VERSION ""

NS_ :

BS_:

BU_: Vector__XXX

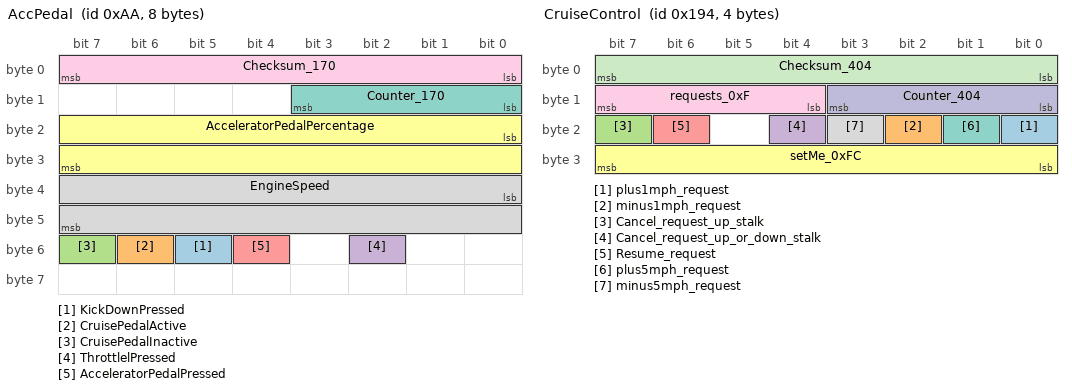
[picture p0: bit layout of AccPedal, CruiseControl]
BO_ 170 AccPedal: 8 Vector__XXX
SG_ KickDownPressed : 53|1@0+ (1,0) [0|1] "" Vector__XXX
SG_ CruisePedalActive : 54|1@0+ (1,0) [0|1] "" Vector__XXX
SG_ CruisePedalInactive : 55|1@0+ (1,0) [0|1] "" Vector__XXX
SG_ ThrottlelPressed : 50|1@0+ (1,0) [0|1] "" Vector__XXX
SG_ AcceleratorPedalPressed : 52|1@0+ (1,0) [0|1] "" Vector__XXX
SG_ AcceleratorPedalPercentage : 16|16@1+ (0.04,0) [0|100] "" Vector__XXX
SG_ Counter_170 : 8|4@1+ (1,0) [0|15] "" Vector__XXX
SG_ EngineSpeed : 32|16@1+ (0.25,0) [0|8000] "rpm" Vector__XXX
SG_ Checksum_170 : 0|8@1- (1,0) [0|127] "" Vector__XXX

BO_ 404 CruiseControl: 4 Vector__XXX
SG_ plus1mph_request : 16|1@0+ (1,0) [0|1] "" Vector__XXX
SG_ minus1mph_request : 18|1@0+ (1,0) [0|1] "" Vector__XXX
SG_ Cancel_request_up_stalk : 23|1@0+ (1,0) [0|1] "" Vector__XXX
SG_ Cancel_request_up_or_down_stalk : 20|1@0+ (1,0) [0|1] "" Vector__XXX
SG_ Resume_request : 22|1@0+ (1,0) [0|1] "" Vector__XXX
SG_ setMe_0xFC : 31|8@0+ (1,0) [0|255] "" Vector__XXX
SG_ plus5mph_request : 17|1@0+ (1,0) [0|1] "" Vector__XXX
SG_ minus5mph_request : 19|1@0+ (1,0) [0|1] "" Vector__XXX
SG_ requests_0xF : 15|4@0+ (1,0) [0|15] "" Vector__XXX
SG_ Counter_404 : 11|4@0+ (1,0) [0|15] "" Vector__XXX
SG_ Checksum_404 : 7|8@0+ (1,0) [0|15] "" Vector__XXX

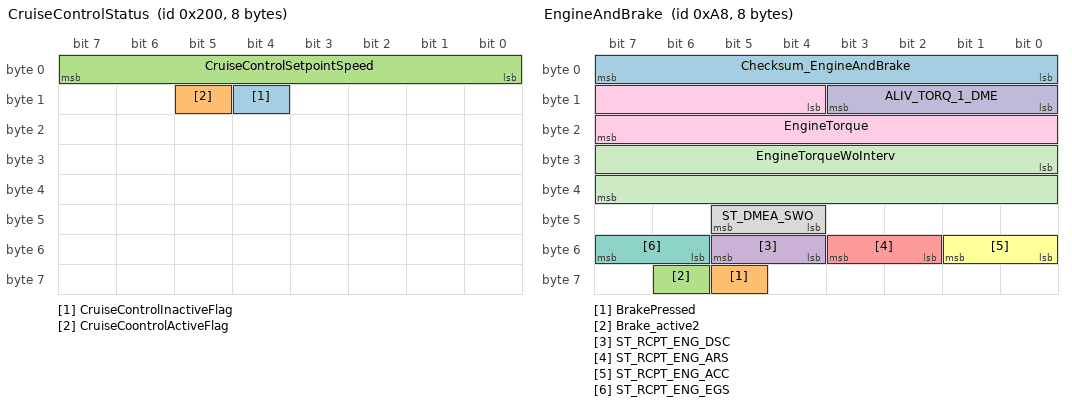
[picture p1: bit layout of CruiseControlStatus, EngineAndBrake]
BO_ 512 CruiseControlStatus: 8 Vector__XXX
SG_ CruiseControlInactiveFlag : 12|1@0+ (1,0) [0|1] "" Vector__XXX
SG_ CruiseCoontrolActiveFlag : 13|1@0+ (1,0) [0|1] "" Vector__XXX
SG_ CruiseControlSetpointSpeed : 7|8@0+ (0.25,0) [0|63.75] "mph" Vector__XXX

BO_ 168 EngineAndBrake: 8 Vector__XXX
SG_ Checksum_EngineAndBrake : 0|8@1+ (1,0) [0|255] "" Vector__XXX
SG_ BrakePressed : 61|1@0+ (1,0) [0|1] "" Vector__XXX
SG_ Brake_active2 : 62|1@0+ (1,0) [0|1] "" Vector__XXX
SG_ ST_RCPT_ENG_DSC : 52|2@1+ (1,0) [0|3] "" Vector__XXX
SG_ ST_RCPT_ENG_ARS : 50|2@1+ (1,0) [0|3] "" Vector__XXX
SG_ ST_RCPT_ENG_ACC : 48|2@1+ (1,0) [0|3] "" Vector__XXX
SG_ ST_RCPT_ENG_EGS : 54|2@1+ (1,0) [0|3] "" Vector__XXX
SG_ ST_DMEA_SWO : 44|2@1+ (1,0) [0|3] "" Vector__XXX
SG_ EngineTorque : 12|12@1- (0.03125,0) [-64|63.96875] "" Vector__XXX
SG_ ALIV_TORQ_1_DME : 8|4@1+ (1,0) [0|15] "" Vector__XXX
SG_ EngineTorqueWoInterv : 24|16@1- (0.03125,0) [-1024|1023.96875] "" Vector__XXX

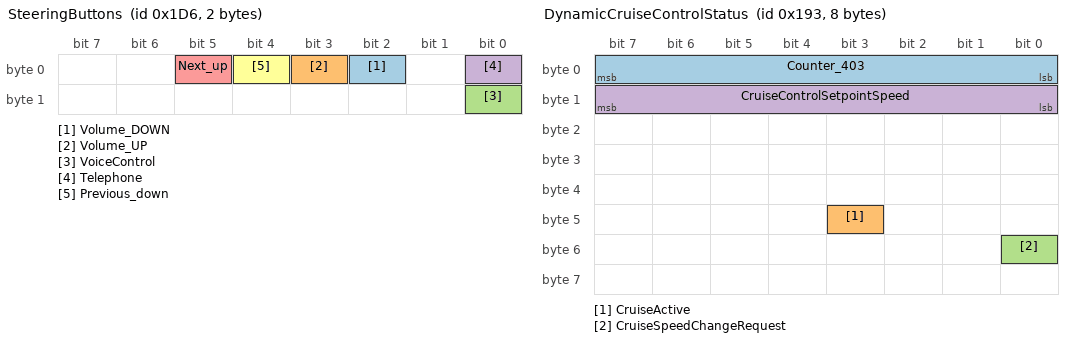
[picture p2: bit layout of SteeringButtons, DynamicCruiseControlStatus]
BO_ 470 SteeringButtons: 2 Vector__XXX
SG_ Volume_DOWN : 2|1@0+ (1,0) [0|1] "" Vector__XXX
SG_ Volume_UP : 3|1@0+ (1,0) [0|1] "" Vector__XXX
SG_ VoiceControl : 8|1@0+ (1,0) [0|1] "" Vector__XXX
SG_ Telephone : 0|1@0+ (1,0) [0|1] "" Vector__XXX
SG_ Next_up : 5|1@0+ (1,0) [0|1] "" Vector__XXX
SG_ Previous_down : 4|1@0+ (1,0) [0|1] "" Vector__XXX

BO_ 403 DynamicCruiseControlStatus: 8 Vector__XXX
SG_ Counter_403 : 7|8@0+ (1,0) [0|255] "" Vector__XXX
SG_ CruiseActive : 43|1@0+ (1,0) [0|1] "" Vector__XXX
SG_ CruiseSpeedChangeRequest : 48|1@0+ (1,0) [0|1] "" Vector__XXX
SG_ CruiseControlSetpointSpeed : 15|8@0+ (1,-2) [0|253] "kph/mph" Vector__XXX

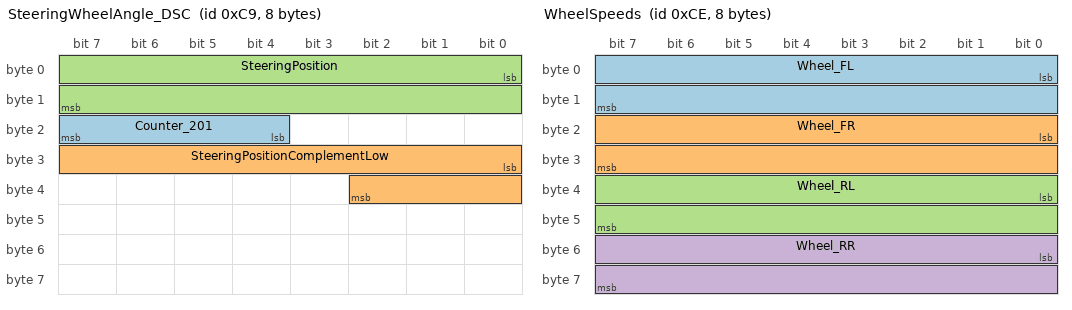
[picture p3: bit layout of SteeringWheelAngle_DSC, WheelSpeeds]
BO_ 201 SteeringWheelAngle_DSC: 8 Vector__XXX
SG_ Counter_201 : 20|4@1+ (1,0) [0|15] "" Vector__XXX
SG_ SteeringPositionComplementLow : 24|11@1- (1,0) [0|1] "" Vector__XXX
SG_ SteeringPosition : 0|16@1- (0.0428316886,0) [-600|600] "deg" Vector__XXX

BO_ 206 WheelSpeeds: 8 Vector__XXX
SG_ Wheel_FL : 0|16@1- (0.0625,0) [0|255] "kph" Vector__XXX
SG_ Wheel_FR : 16|16@1- (0.0625,0) [0|255] "kph" Vector__XXX
SG_ Wheel_RL : 32|16@1- (0.0625,0) [0|255] "kph" Vector__XXX
SG_ Wheel_RR : 48|16@1- (0.0625,0) [0|255] "kph" Vector__XXX

BO_ 884 WheelToleranceAdjustment: 8 Vector__XXX

BO_ 678 WiperSwitch: 8 Vector__XXX
SG_ AutoWipersOn : 0|1@1+ (1,0) [0|1] "" Vector__XXX

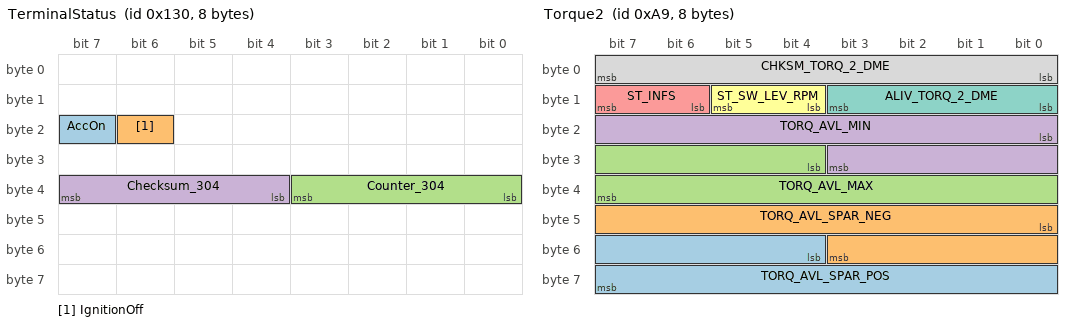
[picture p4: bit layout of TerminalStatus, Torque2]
BO_ 304 TerminalStatus: 8 Vector__XXX
SG_ AccOn : 23|1@1+ (1,0) [0|1] "" Vector__XXX
SG_ IgnitionOff : 22|1@1+ (1,0) [0|1] "" Vector__XXX
SG_ Counter_304 : 32|4@1+ (1,0) [0|15] "" Vector__XXX
SG_ Checksum_304 : 36|4@1+ (1,0) [0|15] "" Vector__XXX

BO_ 169 Torque2: 8 Vector__XXX
SG_ TORQ_AVL_SPAR_POS : 52|12@1- (0.5,0) [-1023.5|1023.5] "Nm" Vector__XXX
SG_ TORQ_AVL_SPAR_NEG : 40|12@1- (0.5,0) [-1023.5|1023.5] "Nm" Vector__XXX
SG_ TORQ_AVL_MAX : 28|12@1- (0.5,0) [-1023.5|1023.5] "Nm" Vector__XXX
SG_ TORQ_AVL_MIN : 16|12@1- (0.5,0) [-1023.5|1023.5] "Nm" Vector__XXX
SG_ ST_INFS : 14|2@1+ (1,0) [0|3] "" Vector__XXX
SG_ ST_SW_LEV_RPM : 12|2@1+ (1,0) [0|3] "" Vector__XXX
SG_ ALIV_TORQ_2_DME : 8|4@1+ (1,0) [0|15] "" Vector__XXX
SG_ CHKSM_TORQ_2_DME : 0|8@1+ (1,0) [0|255] "" Vector__XXX

BO_ 184 TorqueTransmisionRequest: 8 Vector__XXX
SG_ Checksum_184 : 0|8@1+ (1,0) [0|15] "" Vector__XXX
SG_ Counter_184 : 8|4@1+ (1,0) [0|15] "" Vector__XXX

BO_ 196 SteeringWheelAngle: 7 Vector__XXX
SG_ SteeringSpeed : 24|16@1- (0.0428316886,0) [0|255] "degree/s" Vector__XXX
SG_ SteeringPosition : 0|16@1- (0.0428316886,0) [-600|600] "degree" Vector__XXX

BO_ 180 WheelTorqueDriveTrain1: 8 Vector__XXX

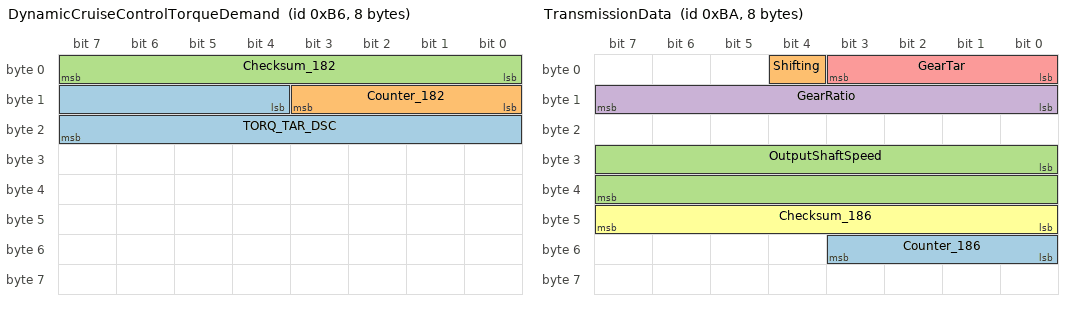
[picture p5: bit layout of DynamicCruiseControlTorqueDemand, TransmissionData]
BO_ 182 DynamicCruiseControlTorqueDemand: 8 Vector__XXX
SG_ TORQ_TAR_DSC : 12|12@1- (0.5,0) [0|1000] "" Vector__XXX
SG_ Counter_182 : 8|4@1+ (1,0) [0|14] "" Vector__XXX
SG_ Checksum_182 : 0|8@1+ (1,0) [0|15] "" Vector__XXX

BO_ 186 TransmissionData: 8 Vector__XXX
SG_ Counter_186 : 48|4@1+ (1,0) [0|14] "" Vector__XXX
SG_ Shifting : 4|1@1+ (1,0) [0|1] "" Vector__XXX
SG_ OutputShaftSpeed : 24|16@1- (0.125,0) [0|255] "rpm" Vector__XXX
SG_ GearRatio : 8|8@1+ (0.05,0) [0|12.75] "" Vector__XXX
SG_ GearTar : 0|4@1+ (1,-4) [0|11] "" Vector__XXX
SG_ Checksum_186 : 40|8@1+ (1,0) [0|15] "" Vector__XXX

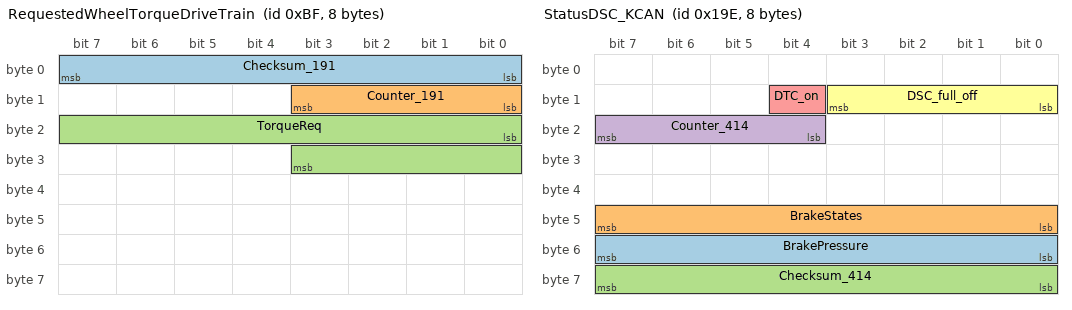
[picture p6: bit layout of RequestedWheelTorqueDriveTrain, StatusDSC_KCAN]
BO_ 191 RequestedWheelTorqueDriveTrain: 8 Vector__XXX
SG_ Checksum_191 : 0|8@1+ (1,0) [0|19] "" Vector__XXX
SG_ Counter_191 : 8|4@1- (1,0) [0|7] "" Vector__XXX
SG_ TorqueReq : 16|12@1- (0.5,350) [-674|1023.96875] "" Vector__XXX

BO_ 414 StatusDSC_KCAN: 8 Vector__XXX
SG_ BrakePressure : 48|8@1- (1,0) [0|127] "" Vector__XXX
SG_ BrakeStates : 40|8@1+ (1,0) [0|255] "" Vector__XXX
SG_ Checksum_414 : 56|8@1+ (1,0) [0|15] "" Vector__XXX
SG_ Counter_414 : 20|4@1+ (1,0) [0|15] "" Vector__XXX
SG_ DTC_on : 12|1@1+ (1,0) [0|1] "" Vector__XXX
SG_ DSC_full_off : 8|4@1+ (1,0) [0|15] "" Vector__XXX

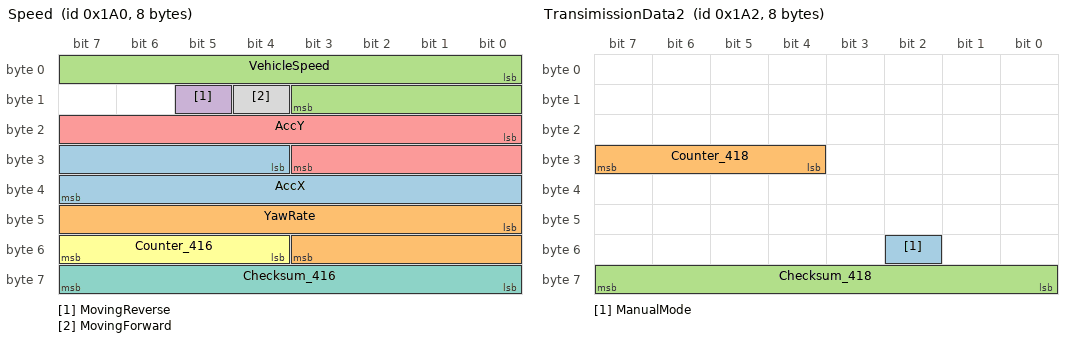
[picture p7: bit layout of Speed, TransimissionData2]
BO_ 416 Speed: 8 Vector__XXX
SG_ AccX : 28|12@1- (1,0) [0|15] "" Vector__XXX
SG_ YawRate : 40|12@1- (1,0) [0|255] "" Vector__XXX
SG_ VehicleSpeed : 0|12@1- (0.103,0) [0|210.841] "kph" Vector__XXX
SG_ MovingReverse : 13|1@1+ (1,0) [0|1] "" Vector__XXX
SG_ AccY : 16|12@1- (1,0) [0|255] "" Vector__XXX
SG_ Counter_416 : 52|4@1+ (1,0) [0|14] "" Vector__XXX
SG_ Checksum_416 : 56|8@1+ (1,0) [0|15] "" Vector__XXX
SG_ MovingForward : 12|1@1+ (1,0) [0|1] "" Vector__XXX

BO_ 418 TransimissionData2: 8 Vector__XXX
SG_ ManualMode : 50|1@0+ (1,0) [0|1] "" Vector__XXX
SG_ Counter_418 : 28|4@1+ (1,0) [0|14] "" Vector__XXX
SG_ Checksum_418 : 56|8@1+ (1,0) [0|15] "" Vector__XXX

BO_ 690 WheelPressure_KCAN: 8 Vector__XXX

BO_ 691 AccelerationData: 8 Vector__XXX

BO_ 402 GearSelectorSwitch_1: 4 Vector__XXX
SG_ Counter_402 : 24|4@1+ (1,0) [0|14] "" Vector__XXX

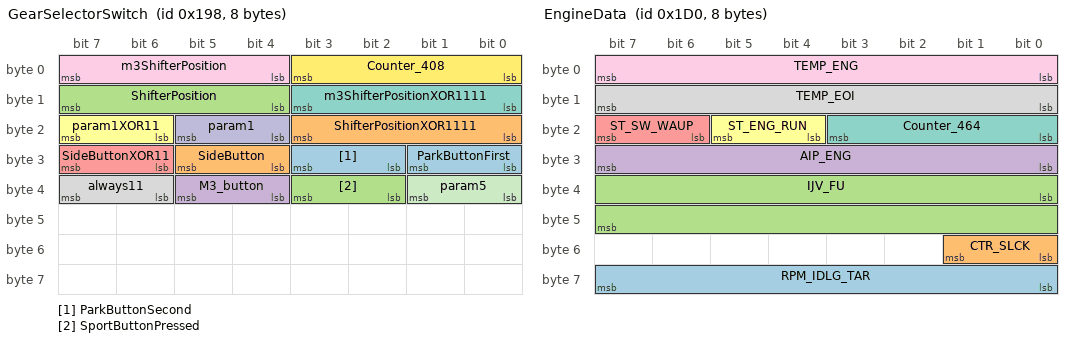
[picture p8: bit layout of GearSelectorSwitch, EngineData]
BO_ 408 GearSelectorSwitch: 8 Vector__XXX
SG_ ParkButtonSecond : 26|2@1+ (1,0) [0|3] "" Vector__XXX
SG_ SideButton : 28|2@1+ (1,0) [0|3] "" Vector__XXX
SG_ SportButtonPressed : 34|2@1+ (1,0) [0|3] "" Vector__XXX
SG_ M3_button : 36|2@1+ (1,0) [0|3] "" Vector__XXX
SG_ SideButtonXOR11 : 30|2@1+ (1,0) [0|3] "" Vector__XXX
SG_ param1XOR11 : 22|2@1+ (1,0) [0|3] "" Vector__XXX
SG_ m3ShifterPositionXOR1111 : 8|4@1+ (1,0) [0|15] "" Vector__XXX
SG_ always11 : 38|2@1+ (1,0) [0|3] "" Vector__XXX
SG_ m3ShifterPosition : 4|4@1+ (1,0) [0|15] "" Vector__XXX
SG_ param1 : 20|2@1+ (1,0) [0|3] "" Vector__XXX
SG_ param5 : 32|2@1+ (1,0) [0|3] "" Vector__XXX
SG_ Counter_408 : 0|4@1+ (1,0) [0|14] "" Vector__XXX
SG_ ParkButtonFirst : 24|2@1+ (1,0) [0|3] "" Vector__XXX
SG_ ShifterPositionXOR1111 : 16|4@1+ (1,0) [0|15] "" Vector__XXX
SG_ ShifterPosition : 12|4@1+ (1,0) [0|15] "" Vector__XXX

BO_ 422 DistanceRoute: 8 Vector__XXX

BO_ 436 InstrumentClusterStatus_KOMBI: 8 Vector__XXX
SG_ HandbrakeActive : 41|1@1+ (1,0) [0|1] "" Vector__XXX

BO_ 464 EngineData: 8 Vector__XXX
SG_ RPM_IDLG_TAR : 56|8@1+ (5,0) [0|1270] "1/min" Vector__XXX
SG_ CTR_SLCK : 48|2@1+ (1,0) [0|3] "" Vector__XXX
SG_ IJV_FU : 32|16@1+ (1,-48) [-48|65487] "C" Vector__XXX
SG_ AIP_ENG : 24|8@1+ (2,598) [600|1106] "hPa" Vector__XXX
SG_ ST_SW_WAUP : 22|2@1+ (1,0) [0|3] "" Vector__XXX
SG_ ST_ENG_RUN : 20|2@1+ (1,0) [0|3] "" Vector__XXX
SG_ Counter_464 : 16|4@1+ (1,0) [0|14] "" Vector__XXX
SG_ TEMP_EOI : 8|8@1+ (1,-48) [-48|207] "C" Vector__XXX
SG_ TEMP_ENG : 0|8@1+ (1,-48) [-48|207] "C" Vector__XXX

BO_ 945 TransmissionData3: 8 Vector__XXX
SG_ Checksum_946 : 0|8@1+ (1,0) [0|19] "" Vector__XXX
SG_ Counter_945 : 8|4@1+ (1,0) [0|14] "" Vector__XXX

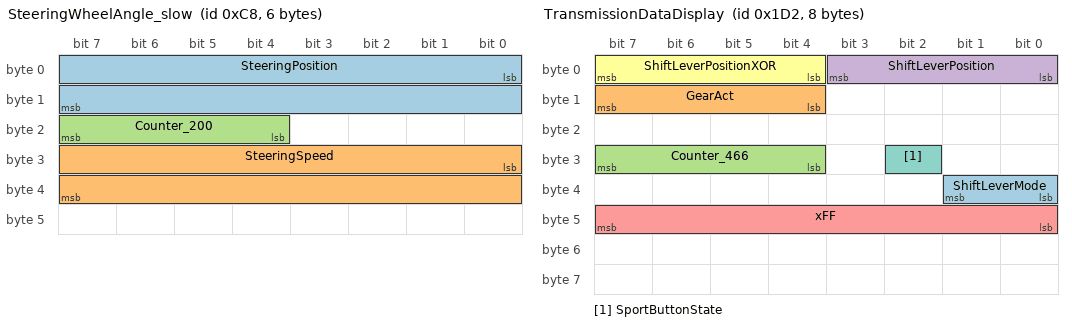
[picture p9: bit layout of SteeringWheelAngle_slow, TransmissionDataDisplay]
BO_ 200 SteeringWheelAngle_slow: 6 Vector__XXX
SG_ SteeringPosition : 0|16@1- (0.0428316886,0) [-600|600] "degree" Vector__XXX
SG_ SteeringSpeed : 24|16@1- (0.0428316886,0) [-1403.5087720448|1403.4659403562] "degree/s" Vector__XXX
SG_ Counter_200 : 20|4@1+ (1,0) [0|15] "" Vector__XXX

BO_ 466 TransmissionDataDisplay: 8 Vector__XXX
SG_ ShiftLeverMode : 32|2@1+ (1,0) [0|3] "" Vector__XXX
SG_ GearAct : 12|4@1+ (1,-4) [0|11] "" Vector__XXX
SG_ Counter_466 : 28|4@1+ (1,0) [0|14] "" Vector__XXX
SG_ ShiftLeverPosition : 0|4@1+ (1,0) [0|8] "" Vector__XXX
SG_ xFF : 40|8@1+ (1,0) [0|255] "" Vector__XXX
SG_ ShiftLeverPositionXOR : 4|4@1+ (1,0) [0|15] "" Vector__XXX
SG_ SportButtonState : 26|1@1+ (1,0) [0|1] "" Vector__XXX

BO_ 437 HeatFlow_LoadTorqueClimate: 8 Vector__XXX

BO_ 1152 NetworkManagment1: 8 Vector__XXX

BO_ 1170 NetworkManagment2: 8 Vector__XXX

BO_ 1175 NetworkManagment3: 8 Vector__XXX

BO_ 1176 NetworkManagment4: 8 Vector__XXX

BO_ 1193 NetworkManagment5: 8 Vector__XXX

BO_ 1246 GWS_ShiftLeverHeartbeat: 8 Vector__XXX
SG_ IgnOff : 12|1@0+ (1,0) [0|1] "" Vector__XXX

BO_ 438 HeatFlowEngine: 8 Vector__XXX

BO_ 784 AmbientTemperature_RelativeTime: 8 Vector__XXX

BO_ 821 ElectricFuelPumpStatus: 8 Vector__XXX

BO_ 1007 EngineOBD_data: 8 Vector__XXX

BO_ 1432 ServicesDKG: 8 Vector__XXX

BO_ 309 CrashDisconnectControl: 8 Vector__XXX

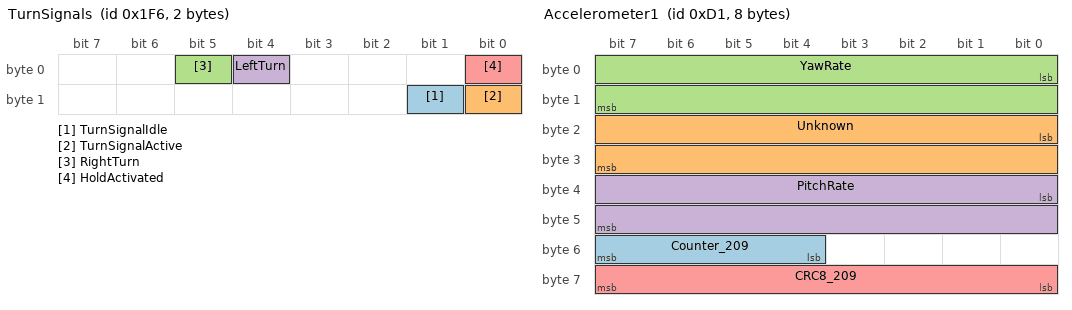
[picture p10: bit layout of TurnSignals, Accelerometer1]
BO_ 502 TurnSignals: 2 Vector__XXX
SG_ TurnSignalIdle : 9|1@0+ (1,0) [0|1] "" Vector__XXX
SG_ TurnSignalActive : 8|1@0+ (1,0) [0|1] "" Vector__XXX
SG_ RightTurn : 5|1@0+ (1,0) [0|1] "" Vector__XXX
SG_ LeftTurn : 4|1@1+ (1,0) [0|1] "" Vector__XXX
SG_ HoldActivated : 0|1@1+ (1,0) [0|1] "" Vector__XXX

BO_ 514 Dimming: 8 Vector__XXX

BO_ 538 LampStatus: 8 Vector__XXX

BO_ 550 RainSensorWiperSpeed: 8 Vector__XXX

BO_ 578 ClimateFrontStatus: 8 Vector__XXX

BO_ 704 LCD_lighting: 8 Vector__XXX

BO_ 758 LightControl: 8 Vector__XXX

BO_ 760 Time_Date: 8 Vector__XXX

BO_ 762 OccupancySeatBeltContact: 8 Vector__XXX
SG_ NEW_SIGNAL_1 : 8|8@1+ (1,0) [0|255] "" Vector__XXX
SG_ NEW_SIGNAL_2 : 0|8@1+ (1,0) [0|15] "" Vector__XXX

BO_ 764 TrunkStatus: 8 Vector__XXX

BO_ 797 TirePressureStatus: 8 Vector__XXX

BO_ 816 Range_Mileage: 8 Vector__XXX

BO_ 823 StatusFuelControl: 8 Vector__XXX

BO_ 897 EngineOilLevel: 8 Vector__XXX

BO_ 940 RunOnTimeTerminal30: 8 Vector__XXX

BO_ 947 PowerManagmentConsumptionControl: 8 Vector__XXX

BO_ 948 PowerBatteryVoltage: 8 Vector__XXX
SG_ BatteryVoltage : 7|24@0+ (0.001,0) [0|16777.215] "" Vector__XXX

BO_ 958 PowerRunningTime: 8 Vector__XXX

BO_ 1408 ServicesKGM: 8 Vector__XXX

BO_ 1426 ServicesDME: 8 Vector__XXX

BO_ 1449 ServicesDSC: 8 Vector__XXX

BO_ 1504 ServicesKOMBI: 8 Vector__XXX

BO_ 1522 ServicesKBM: 8 Vector__XXX

BO_ 209 Accelerometer1: 8 Vector__XXX
SG_ Counter_209 : 52|4@1+ (1,0) [0|15] "" Vector__XXX
SG_ Unknown : 16|16@1- (1,0) [0|32767] "" Vector__XXX
SG_ YawRate : 0|16@1- (1,0) [0|7] "" Vector__XXX
SG_ PitchRate : 32|16@1- (1,0) [0|32767] "" Vector__XXX
SG_ CRC8_209 : 56|8@1+ (1,0) [0|255] "" Vector__XXX

BO_ 172 WheelTorqueDrivetrain2: 8 Vector__XXX

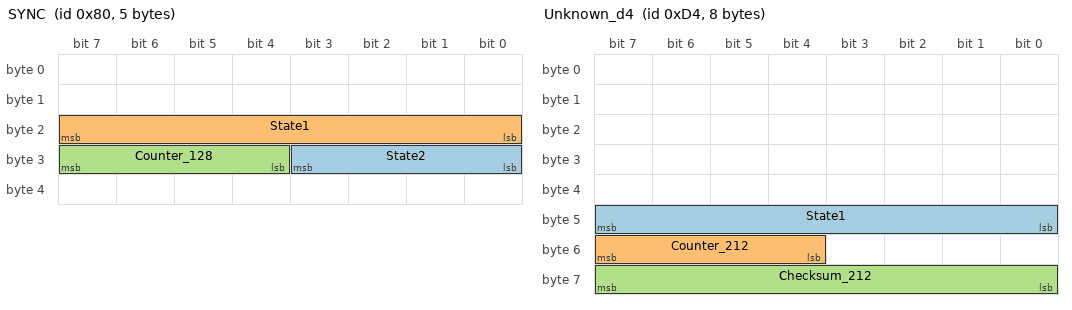
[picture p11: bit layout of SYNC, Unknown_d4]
BO_ 128 SYNC: 5 Vector__XXX
SG_ State2 : 24|4@1+ (1,0) [0|15] "" Vector__XXX
SG_ State1 : 16|8@1+ (1,0) [0|255] "" Vector__XXX
SG_ Counter_128 : 28|4@1+ (1,0) [0|15] "" Vector__XXX

BO_ 320 Unknown140: 2 Vector__XXX
SG_ State : 7|8@0+ (1,0) [0|255] "" Vector__XXX

BO_ 212 Unknown_d4: 8 Vector__XXX
SG_ State1 : 40|8@1+ (1,0) [0|255] "" Vector__XXX
SG_ Counter_212 : 52|4@1+ (1,0) [0|15] "" Vector__XXX
SG_ Checksum_212 : 56|8@1+ (1,0) [0|255] "" Vector__XXX

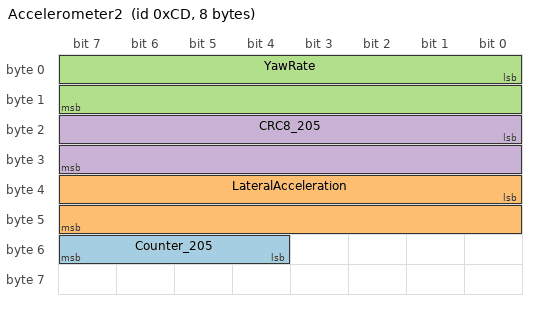
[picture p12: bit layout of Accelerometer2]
BO_ 205 Accelerometer2: 8 Vector__XXX
SG_ Counter_205 : 52|4@1+ (1,0) [0|15] "" Vector__XXX
SG_ LateralAcceleration : 32|16@1- (1,0) [0|255] "" Vector__XXX
SG_ YawRate : 0|16@1- (1,0) [0|255] "" Vector__XXX
SG_ CRC8_205 : 16|16@1- (1,0) [0|32767] "" Vector__XXX

BO_ 790 OperationPushButtonDTC: 2 Vector__XXX
SG_ setMe_0x3FFF : 2|14@1+ (1,0) [0|63] "" Vector__XXX
SG_ DTC_pressed : 0|1@1+ (1,0) [0|1] "" Vector__XXX

BO_ 1577 Unknown_629: 8 Vector__XXX

BO_ 133 Synchronization_SC_VDA: 8 Vector__XXX

BO_ 173 Delay_request_ACC: 8 Vector__XXX

BO_ 177 Torque_request_steering: 8 Vector__XXX

BO_ 181 Torque_request_EGS: 8 Vector__XXX
SG_ Checksum_Torque_request_EGS : 0|8@1+ (1,0) [0|255] "" Vector__XXX
SG_ Gearbox_temperature : 56|8@1+ (1,0) [0|255] "C" Vector__XXX

BO_ 183 Torque_request_ACC: 8 Vector__XXX

BO_ 187 Target_torque_request: 8 Vector__XXX

BO_ 188 Status_target_torque_conversion: 8 Vector__XXX

BO_ 190 Alive_Counter: 8 Vector__XXX

BO_ 192 Alive_Central_Gateway: 8 Vector__XXX

BO_ 193 Alive_counter_telephone: 8 Vector__XXX

BO_ 213 Request_wheel_torque_brake: 8 Vector__XXX

BO_ 215 Alive_Counter_Security: 8 Vector__XXX

BO_ 216 CLU1_VDA: 8 Vector__XXX

BO_ 225 Wheel_torque_brake: 8 Vector__XXX

BO_ 226 Status_central_locking_BFT: 8 Vector__XXX

BO_ 227 CLU2_VDA: 8 Vector__XXX

BO_ 230 Status_central_locking_BFTH: 8 Vector__XXX

BO_ 234 Status_central_locking_FAT: 8 Vector__XXX

BO_ 238 Central_locking_status_FATH: 8 Vector__XXX

BO_ 242 Status_central_locking_HK: 8 Vector__XXX

BO_ 244 CLU3_VDA: 8 Vector__XXX

BO_ 247 lateral_dynamics_ARS_VDM: 8 Vector__XXX

BO_ 249 Vertical_dynamics_VDM_ARS: 8 Vector__XXX

BO_ 250 Control_window_lifter_FAT: 8 Vector__XXX

BO_ 251 Control_window_lifter_BFT: 8 Vector__XXX

BO_ 252 Control_window_lifter_FATH: 8 Vector__XXX

BO_ 253 Control_window_lifter_BFTH: 8 Vector__XXX

BO_ 254 Voltage_level_sensors: 8 Vector__XXX

BO_ 280 Exchange_AFS_DSC: 8 Vector__XXX

BO_ 286 Control_interventions_DSC_AFS: 8 Vector__XXX

BO_ 288 Status_partial_setpoints_AFS_DSC: 8 Vector__XXX

BO_ 298 Sensor_data_ROSE: 8 Vector__XXX

BO_ 300 input_data_ROSE: 8 Vector__XXX

BO_ 336 Request_1_ACC: 8 Vector__XXX

BO_ 339 Request_2_ACC: 8 Vector__XXX

BO_ 345 Object_data_ACC: 8 Vector__XXX

BO_ 348 Status_ACC: 8 Vector__XXX

BO_ 351 Requirement_angle_FFP: 8 Vector__XXX

BO_ 357 CLU_Status_VDA: 8 Vector__XXX

BO_ 370 Acknowledgment_request_Kombinati: 8 Vector__XXX

BO_ 373 Display_motor_data: 8 Vector__XXX

BO_ 400 display_ACC: 8 Vector__XXX

BO_ 405 Operation_push_button_MSA: 8 Vector__XXX

BO_ 419 Raw_data_longitudinal_accelerati: 8 Vector__XXX

BO_ 423 actuation_request_EMF: 8 Vector__XXX

BO_ 426 Effect_ErgoCommander: 8 Vector__XXX

BO_ 428 Status_ARS_module: 8 Vector__XXX

BO_ 440 Operation_ErgoCommander: 8 Vector__XXX

BO_ 450 Distance_message_PDC: 8 Vector__XXX

BO_ 451 Distance_message_2_PDC: 8 Vector__XXX

BO_ 454 Acoustic_message_PDC: 8 Vector__XXX

BO_ 472 Operation_air_conditioning_air_d: 8 Vector__XXX

BO_ 473 Operation_pushbutton_MDrive: 8 Vector__XXX

BO_ 474 Climate_control_remote_control: 8 Vector__XXX

BO_ 476 Operation_stratification_seat_he: 8 Vector__XXX

BO_ 478 Air_conditioning_controls_rear: 8 Vector__XXX

BO_ 480 Operation_air_conditioning_air_d: 8 Vector__XXX

BO_ 482 Operation_air_conditioning_front: 8 Vector__XXX

BO_ 483 Operation_pushbutton_interior_li: 8 Vector__XXX

BO_ 487 Operation_seat_heating_seat_clim: 8 Vector__XXX

BO_ 488 Operation_seat_heating_seat_clim: 8 Vector__XXX

BO_ 490 Steering_column_adjustment_contr: 8 Vector__XXX

BO_ 491 Operation_active_seat_FA: 8 Vector__XXX

BO_ 492 Operation_active_seat_BF: 8 Vector__XXX

BO_ 494 Steering_column_switch_operation: 8 Vector__XXX

BO_ 499 Operation_seat_memory_FA: 8 Vector__XXX

BO_ 504 Operation_SHD_MDS: 8 Vector__XXX

BO_ 507 Status_EPS: 8 Vector__XXX

BO_ 508 Status_AFS: 8 Vector__XXX

BO_ 509 Status_request_EMF_KCAN: 8 Vector__XXX

BO_ 510 Crash: 8 Vector__XXX

BO_ 513 Status_EMF_KCAN: 8 Vector__XXX

BO_ 517 Acoustic_request_Kombi: 8 Vector__XXX

BO_ 518 Control_Display_Shiftlights: 8 Vector__XXX

BO_ 523 Memory_adjustment: 8 Vector__XXX

BO_ 524 Steering_column_control: 8 Vector__XXX

BO_ 525 Position_steering_column: 8 Vector__XXX

BO_ 528 Operation_HUD: 8 Vector__XXX

BO_ 529 Status_HUD: 8 Vector__XXX

BO_ 530 Height_levels_air_spring: 8 Vector__XXX

BO_ 540 Operation_NightVision: 8 Vector__XXX

BO_ 542 Status_NightVision: 8 Vector__XXX

BO_ 548 Operation_push_button_NSW: 8 Vector__XXX

BO_ 552 Operation_special_function: 8 Vector__XXX

BO_ 554 Status_BFS: 8 Vector__XXX

BO_ 556 Operation_push_button_NSL: 8 Vector__XXX

BO_ 558 Status_BFSH: 8 Vector__XXX

BO_ 562 Status_FAS: 8 Vector__XXX

BO_ 566 Status_FASH: 8 Vector__XXX

BO_ 570 Status_radio_key: 8 Vector__XXX

BO_ 571 Status_climate_front_extended: 8 Vector__XXX

BO_ 573 Request_display_climate: 8 Vector__XXX

BO_ 574 Status_Klima_Fond: 8 Vector__XXX

BO_ 582 Status_air_conditioning_front_co: 8 Vector__XXX

BO_ 584 Status_rear_view_camera: 8 Vector__XXX

BO_ 585 Control_rear_view_camera: 8 Vector__XXX

BO_ 586 Status_PDC: 8 Vector__XXX

BO_ 587 Status_door_sensors: 8 Vector__XXX

BO_ 594 Wiper_status: 8 Vector__XXX

BO_ 598 Challenge_Passive_Access: 8 Vector__XXX

BO_ 600 Status_Transmission_Passive_Acce: 8 Vector__XXX

BO_ 604 Operation_of_climate_additional_: 8 Vector__XXX

BO_ 621 Operation_blinds_MK: 8 Vector__XXX

BO_ 622 Control_FH_SHD_central_comfort: 8 Vector__XXX

BO_ 635 Status_Shiftlights: 8 Vector__XXX

BO_ 637 Status_convertible_top_manual_co: 8 Vector__XXX

BO_ 638 Status_convertible_top_convertib: 8 Vector__XXX

BO_ 639 Status_central_locking_convertib: 8 Vector__XXX

BO_ 642 Control_security_vehicle_2: 8 Vector__XXX

BO_ 644 Control_remote_start_safety_vehi: 8 Vector__XXX

BO_ 646 Electrochromic_control: 8 Vector__XXX

BO_ 652 Pushbutton_vertical_dynamics: 8 Vector__XXX

BO_ 653 Operation_pushbutton_sport: 8 Vector__XXX

BO_ 656 Control_response_hydrogen_vehicl: 8 Vector__XXX

BO_ 658 Control_high_beam_assistant: 8 Vector__XXX

BO_ 670 Central_locking_control_for_secu: 8 Vector__XXX

BO_ 671 Remote_control_FondCommander: 8 Vector__XXX

BO_ 672 Central_locking_control: 8 Vector__XXX

BO_ 674 Operation_of_climate_stand_funct: 8 Vector__XXX

BO_ 676 Operation_personalization: 8 Vector__XXX

BO_ 692 DWA_Alarm: 8 Vector__XXX

BO_ 694 Control_horn_DWA: 8 Vector__XXX

BO_ 696 Operation_onboard_computer: 8 Vector__XXX

BO_ 697 Operation_RSE: 8 Vector__XXX

BO_ 698 Stopwatch: 8 Vector__XXX

BO_ 701 Request_switching_display: 8 Vector__XXX

BO_ 702 Switch_status_display: 8 Vector__XXX

BO_ 703 Water_valve_control: 8 Vector__XXX

BO_ 706 Temperatur_Ist_Fond: 8 Vector__XXX

BO_ 711 Display_Kombination_extended: 8 Vector__XXX

BO_ 714 Outside_temperature: 8 Vector__XXX

BO_ 716 Control_monitor_rear: 8 Vector__XXX

BO_ 718 Control_monitor: 8 Vector__XXX

BO_ 719 Status_of_auxiliary_water_pump: 8 Vector__XXX

BO_ 720 Status_Sensor_AUC: 8 Vector__XXX

BO_ 721 Status_fitting_window_V: 8 Vector__XXX

BO_ 722 Status_pressure_refrigeration_ci: 8 Vector__XXX

BO_ 723 Status_stratification_rear: 8 Vector__XXX

BO_ 725 Status_heating_rear_window: 8 Vector__XXX

BO_ 726 Status_valve_air_conditioning_co: 8 Vector__XXX

BO_ 730 Status_tailgate_lift: 8 Vector__XXX

BO_ 734 Switch_control_display: 8 Vector__XXX

BO_ 738 Status_setting_video_night_visio: 8 Vector__XXX

BO_ 739 Status_setting_video_rear_view_c: 8 Vector__XXX

BO_ 740 Status_trailer: 8 Vector__XXX

BO_ 742 Status_of_air_distribution_FA: 8 Vector__XXX

BO_ 746 Status_air_distribution_BF: 8 Vector__XXX

BO_ 750 Status_climate_additional_progra: 8 Vector__XXX

BO_ 752 Status_air_condition_functions: 8 Vector__XXX

BO_ 753 Status_driver_detection: 8 Vector__XXX

BO_ 755 Display_switching_instruction: 8 Vector__XXX

BO_ 756 Air_conditioning_control_SH_ZH_a: 8 Vector__XXX

BO_ 759 Units: 8 Vector__XXX

BO_ 768 Status_RSE: 8 Vector__XXX

BO_ 772 Status_Gang: 8 Vector__XXX

BO_ 773 Operation_button_convertible_top: 8 Vector__XXX

BO_ 774 Vehicle_tilt: 8 Vector__XXX

BO_ 775 Operation_button_flap_convertibl: 8 Vector__XXX

BO_ 776 Status_MSA: 8 Vector__XXX

BO_ 785 Refill_quantity: 8 Vector__XXX

BO_ 786 Service_Call_Teleservice: 8 Vector__XXX

BO_ 787 Status_Service_Call_Teleservice: 8 Vector__XXX

BO_ 788 Status_driving_light: 8 Vector__XXX

BO_ 789 Vehicle_mode: 8 Vector__XXX

BO_ 791 Operation_button_parking_aids: 8 Vector__XXX

BO_ 792 Status_antennas_Passive_Access: 8 Vector__XXX

BO_ 793 Operation_push_button_RDC: 8 Vector__XXX

BO_ 794 Operation_button_HDC: 8 Vector__XXX

BO_ 795 Operation_of_tailgate_interior_b: 8 Vector__XXX

BO_ 796 Status_tire_pressure: 8 Vector__XXX

BO_ 801 Operation_button_camera_BF: 8 Vector__XXX

BO_ 802 Damper_current: 8 Vector__XXX

BO_ 806 Status_damper_program: 8 Vector__XXX

BO_ 808 Relativzeit: 8 Vector__XXX

BO_ 813 Display_HDC: 8 Vector__XXX

BO_ 814 Status_climate_internal_control_: 8 Vector__XXX

BO_ 817 Programming_of_step_cruise_contr: 8 Vector__XXX

BO_ 818 Driver_display_speed_range: 8 Vector__XXX

BO_ 822 Display_check_control_message_ro: 8 Vector__XXX

BO_ 824 Control_display_check_control_me: 8 Vector__XXX

BO_ 825 Status_display_climate: 8 Vector__XXX

BO_ 826 Status_Monitor_Front: 8 Vector__XXX

BO_ 828 Status_Monitor_Fond_1: 8 Vector__XXX

BO_ 830 Status_Monitor_Fond_2: 8 Vector__XXX

BO_ 841 Raw_data_level_tank: 8 Vector__XXX

BO_ 843 Seat_back_lock_status_FA: 8 Vector__XXX

BO_ 845 Status_seat_back_lock_BF: 8 Vector__XXX

BO_ 847 Status_contact_handbrake: 8 Vector__XXX
SG_ Handbrake_push : 0|2@1+ (1,0) [0|3] "" Vector__XXX

BO_ 858 Appointment_Condition_Based_Serv: 8 Vector__XXX

BO_ 860 Status_onboard_computer: 8 Vector__XXX

BO_ 862 Onboard_computer_data_trip_data: 8 Vector__XXX

BO_ 864 Data_onboard_computer_start_of_j: 8 Vector__XXX

BO_ 866 Data_onboard_computer_average_va: 8 Vector__XXX

BO_ 868 Data_onboard_computer_arrival: 8 Vector__XXX

BO_ 869 Status_terminal_request: 8 Vector__XXX

BO_ 870 Display_Kombination_external_dis: 8 Vector__XXX

BO_ 871 Control_display_of_demand_orient: 8 Vector__XXX

BO_ 877 Setting_the_driving_dynamics_swi: 8 Vector__XXX

BO_ 886 Status_wear_lamella: 8 Vector__XXX

BO_ 893 Status_DKG: 8 Vector__XXX

BO_ 894 Temperatur_Bremse: 8 Vector__XXX

BO_ 895 Range_of_diesel_exhaust_gas_addi: 8 Vector__XXX

BO_ 896 chassis_number: 8 Vector__XXX

BO_ 898 Electronic_engine_oil_dipstick_M: 8 Vector__XXX

BO_ 899 Motor_data_2: 8 Vector__XXX

BO_ 904 Vehicle_type: 8 Vector__XXX

BO_ 907 Status_battery: 8 Vector__XXX

BO_ 910 Start_speed: 8 Vector__XXX

BO_ 914 Status_System_AFS: 8 Vector__XXX

BO_ 916 RDA_request_data_storage: 8 Vector__XXX

BO_ 917 Coding_power_management: 8 Vector__XXX

BO_ 920 Operation_chassis: 8 Vector__XXX

BO_ 921 Status_MDrive: 6 Vector__XXX

BO_ 926 Operation_time_date: 8 Vector__XXX

BO_ 928 Vehicle_state: 8 Vector__XXX

BO_ 931 Request_Remote_Services: 8 Vector__XXX

BO_ 937 Status_motor_control_CKM: 8 Vector__XXX

BO_ 939 Status_Shiftlights_CKM: 8 Vector__XXX

BO_ 944 Status_gear_reverse: 8 Vector__XXX

BO_ 949 Status_water_valve: 8 Vector__XXX

BO_ 950 Position_window_lifter_FAT: 8 Vector__XXX

BO_ 951 Position_window_lifter_FATH: 8 Vector__XXX

BO_ 952 Position_window_regulator_BFT: 8 Vector__XXX

BO_ 953 Position_window_regulator_BFTH: 8 Vector__XXX

BO_ 954 Position_SHD: 8 Vector__XXX

BO_ 956 Position_window_lifter_security_: 8 Vector__XXX

BO_ 957 Status_consumer_shutdown: 8 Vector__XXX

BO_ 959 Position_window_rear_window: 8 Vector__XXX

BO_ 960 Configuration_FAS: 8 Vector__XXX

BO_ 961 Configuration_BFS: 8 Vector__XXX

BO_ 964 Status_EDCK_CKM: 8 Vector__XXX

BO_ 967 Access_radio: 8 Vector__XXX

BO_ 968 Operation_push_button_radio: 8 Vector__XXX

BO_ 974 Radio_audio_control_interface_di: 8 Vector__XXX

BO_ 975 Acknowledgment_access_radio_audi: 8 Vector__XXX

BO_ 979 Status_solar_sensor: 8 Vector__XXX

BO_ 980 Configuration_of_central_locking: 8 Vector__XXX

BO_ 981 Status_central_locking_CKM: 8 Vector__XXX

BO_ 982 Configuration_DWA_CKM: 8 Vector__XXX

BO_ 983 Status_DWA_CKM: 8 Vector__XXX

BO_ 984 Configuration_RLS_CKM: 8 Vector__XXX

BO_ 985 Status_RLS_CKM: 8 Vector__XXX

BO_ 986 Configuration_of_memory_position: 8 Vector__XXX

BO_ 987 Status_memory_positions_CKM: 8 Vector__XXX

BO_ 988 Configuration_light_CKM: 8 Vector__XXX

BO_ 989 Status_light_CKM: 8 Vector__XXX

BO_ 990 Configuration_Climate_CKM: 8 Vector__XXX

BO_ 991 Status_Klima_CKM: 8 Vector__XXX

BO_ 994 Configuration_of_tailgate_CKM: 8 Vector__XXX

BO_ 995 Status_tailgate_CKM: 8 Vector__XXX

BO_ 996 Configuration_rear_view_camera_C: 8 Vector__XXX

CM_ SG_ 170 ThrottlelPressed "Active when accelerator pedal pressed or cruise control: drives";
CM_ SG_ 170 AcceleratorPedalPressed "Active only when driver actually presses the pedal";
CM_ SG_ 170 AcceleratorPedalPercentage "ToDo Factor to be adjusted";
CM_ SG_ 404 plus1mph_request "Appears when +1mph/kph stalk is depressed";
CM_ SG_ 404 minus1mph_request "Appears when -1mph/kph stalk is depressed";
CM_ SG_ 404 Cancel_request_up_stalk "Appears when cancel stalk (up) is depressed";
CM_ SG_ 404 Cancel_request_up_or_down_stalk "Appears when cancel stalk (up or down) is depressed";
CM_ SG_ 404 Resume_request "It appears when resume stalk button is depressed";
CM_ SG_ 404 Counter_404 "Message is sent at higher rate when cruise stalk is pressed";
CM_ SG_ 168 BrakePressed "Brake when driver presses the brake or hill hold";
CM_ SG_ 168 EngineTorque "Engine torque without inertia - combustion torque";
CM_ SG_ 168 ALIV_TORQ_1_DME "Counter TORQ_1";
CM_ SG_ 168 EngineTorqueWoInterv "Engine torque without inertia and without shift intervention";
CM_ SG_ 403 CruiseControlSetpointSpeed "Speed target - unit depends on locale";
CM_ SG_ 169 ALIV_TORQ_2_DME "Counter TORQ_2";
CM_ SG_ 182 TORQ_TAR_DSC "torque target DSC";
CM_ SG_ 186 GearTar "Values corresponds to forward gears. TBD Add enums for park, reverse";
CM_ SG_ 414 DSC_full_off "0x4 enabling, 0xA enabled. TBD";
CM_ SG_ 416 YawRate "Lateral Acceleration";
CM_ SG_ 408 ParkButtonSecond "Redundant buton. 0x1 = pressed;";
CM_ SG_ 408 SideButton "0x1 = pressed;";
CM_ SG_ 408 SportButtonPressed "0x1 = pressed;";
CM_ SG_ 408 M3_button "M3 POWER (?)";
CM_ SG_ 408 SideButtonXOR11 "Complement value";
CM_ SG_ 408 param1 "can not be 0x03. Always 0 in 135i.";
CM_ SG_ 408 param5 "Always 0 in 135i.";
CM_ SG_ 408 ParkButtonFirst "0x1 = pressed";
CM_ SG_ 408 ShifterPosition "0001 = N|R, 0010 = R, 0011 = N|D, 0100 = D, 0101 = -1, 0110 = +1, 0111 = ManualMode, 1000 = inBetween,";
CM_ SG_ 466 ShiftLeverMode "On the dashboard, there are displayed:  D1...D7 in Normal. S1...S6 in Sport.  M1..M7 in Manual";
CM_ SG_ 466 GearAct "TransmissionDataDisplay";
CM_ SG_ 502 TurnSignalIdle "Turn signal off";
CM_ SG_ 502 TurnSignalActive "Turn signal on or transitioning";
CM_ SG_ 502 RightTurn "Indicates right blinker or when steering returning right clears left blinker";
CM_ SG_ 502 LeftTurn "Indicates left blinker or when steering returning left clears right blinker";
CM_ SG_ 502 HoldActivated "Spikes down if blinker cleared with timeout or turn. Stays off if blinker cleared with stalk";
CM_ SG_ 790 setMe_0x3FFF "All ones";
CM_ SG_ 790 DTC_pressed "Traction control off. Message transmitted when pressed. Few presses may be required followed by off.";

BA_DEF_  "BusType" STRING ;
BA_DEF_ SG_  "GenSigStartValue" FLOAT -3.4E+038 3.4E+038;

BA_DEF_DEF_  "BusType" "CAN";
BA_DEF_DEF_  "GenSigStartValue" 0;

BA_ "GenSigStartValue" SG_ 464 AIP_ENG 600;
VAL_ 408 ShifterPosition 1 "D" 2 "S" 3 "N" 4 "R" 5 "P";
VAL_ 464 CTR_SLCK 3 "signal invalid" 2 "requirement Shiftlock" 1 "no requirement Shiftlock" 0 "not allowed";
VAL_ 464 ST_SW_WAUP 3 "signal invalid" 2 "EGS forced switching active" 1 "engine warm" 0 "warming up";
VAL_ 464 ST_ENG_RUN 3 "signal invalid" 2 "engine running" 1 "engine starting" 0 "engine off";
VAL_ 466 ShiftLeverMode 0 "Normal" 1 "Sport" 2 "Manual";
VAL_ 466 ShiftLeverPosition 0 "Off" 1 "P" 2 "R" 4 "N" 8 "D";
